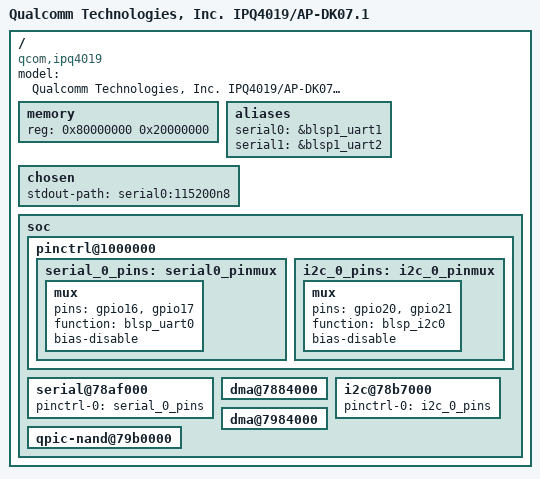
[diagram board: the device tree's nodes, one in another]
// SPDX-License-Identifier: GPL-2.0
// Copyright (c) 2018, The Linux Foundation. All rights reserved.

#include "qcom-ipq4019.dtsi"
#include <dt-bindings/input/input.h>
#include <dt-bindings/gpio/gpio.h>

/ {
	model = "Qualcomm Technologies, Inc. IPQ4019/AP-DK07.1";
	compatible = "qcom,ipq4019";

	memory {
		device_type = "memory";
		reg = <0x80000000 0x20000000>; /* 512MB */
	};

	aliases {
		serial0 = &blsp1_uart1;
		serial1 = &blsp1_uart2;
	};

	chosen {
		stdout-path = "serial0:115200n8";
	};

	soc {
		pinctrl@1000000 {
			serial_0_pins: serial0_pinmux {
				mux {
					pins = "gpio16", "gpio17";
					function = "blsp_uart0";
					bias-disable;
				};
			};

			i2c_0_pins: i2c_0_pinmux {
				mux {
					pins = "gpio20", "gpio21";
					function = "blsp_i2c0";
					bias-disable;
				};
			};
		};

		serial@78af000 {
			pinctrl-0 = <&serial_0_pins>;
			pinctrl-names = "default";
			status = "ok";
		};

		dma@7884000 {
			status = "ok";
		};

		i2c@78b7000 { /* BLSP1 QUP2 */
			pinctrl-0 = <&i2c_0_pins>;
			pinctrl-names = "default";
			status = "ok";
		};

		dma@7984000 {
			status = "ok";
		};

		qpic-nand@79b0000 {
			status = "ok";
		};
	};
};
